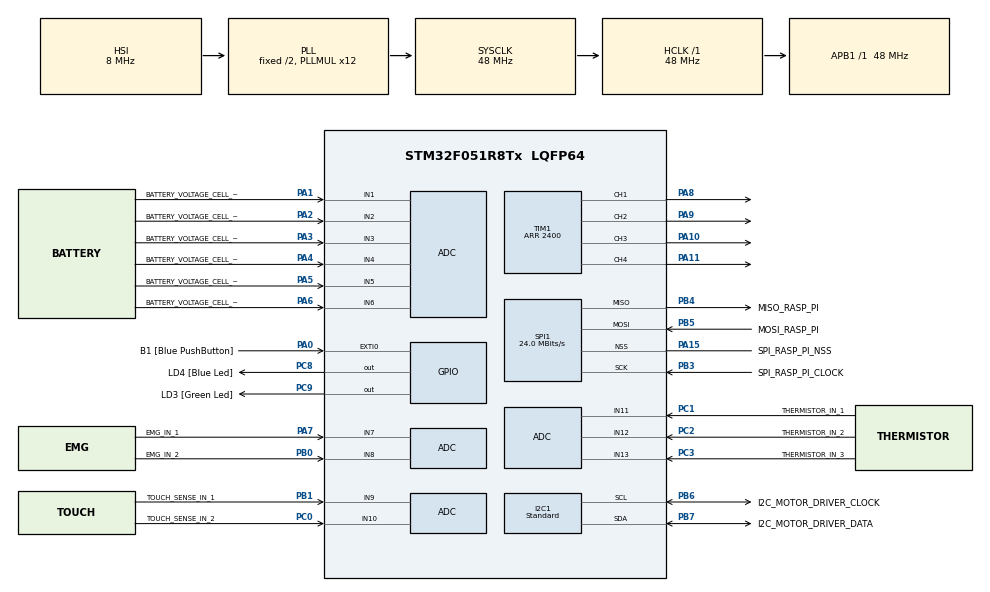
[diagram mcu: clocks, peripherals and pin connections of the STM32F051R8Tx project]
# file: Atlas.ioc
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ADC.ContinuousConvMode=ENABLE
ADC.DMAContinuousRequests=ENABLE
ADC.EOCSelection=EOC_SEQ_CONV
ADC.Overrun=OVR_DATA_OVERWRITTEN
ADC.SamplingTime=ADC_SAMPLETIME_55CYCLES_5
Dma.ADC.0.Direction=DMA_PERIPH_TO_MEMORY
Dma.ADC.0.Instance=DMA1_Channel1
Dma.ADC.0.MemDataAlignment=DMA_MDATAALIGN_HALFWORD
Dma.ADC.0.MemInc=DMA_MINC_ENABLE
Dma.ADC.0.Mode=DMA_CIRCULAR
Dma.ADC.0.PeriphDataAlignment=DMA_PDATAALIGN_HALFWORD
Dma.ADC.0.PeriphInc=DMA_PINC_DISABLE
Dma.ADC.0.Priority=DMA_PRIORITY_LOW
Dma.Request0=ADC
I2C1.I2C_Speed_Mode=I2C_Standard
I2C1.Speed=100
I2C1.Timing=0x2000090E
Mcu.Family=STM32F0
Mcu.Name=STM32F051R8Tx
Mcu.Package=LQFP64
NVIC.DMA1_Channel1_IRQn=true\:0\:0\:false
PA0.GPIO_Label=B1 [Blue PushButton]
PA0.GPIO_ModeDefaultEXTI=GPIO_MODE_EVT_RISING
PA0.GPIO_PuPd=GPIO_NOPULL
PA0.Signal=GPXTI0
PA1.GPIO_Label=BATTERY_VOLTAGE_CELL_IN_1
PA1.GPIO_Mode=GPIO_MODE_ANALOG
PA1.GPIO_PuPd=GPIO_NOPULL
PA1.Mode=IN1
PA1.Signal=ADC_IN1
PA10.Signal=S_TIM1_CH3
PA11.Signal=S_TIM1_CH4
PA13.GPIO_Label=SWDIO
PA13.Mode=Serial-WireDebug
PA13.Signal=SYS_SWDIO
PA14.GPIO_Label=SWCLK
PA14.Mode=Serial-WireDebug
PA14.Signal=SYS_SWCLK
PA15.GPIO_Label=SPI_RASP_PI_NSS
PA15.GPIO_Mode=GPIO_MODE_AF_PP
PA15.GPIO_PuPd=GPIO_NOPULL
PA15.GPIO_Speed=GPIO_SPEED_HIGH
PA15.Mode=NSS_Signal_Hard
PA15.Signal=SPI1_NSS
PA2.GPIO_Label=BATTERY_VOLTAGE_CELL_IN_2
PA2.GPIO_Mode=GPIO_MODE_ANALOG
PA2.GPIO_PuPd=GPIO_NOPULL
PA2.Mode=IN2
PA2.Signal=ADC_IN2
PA3.GPIO_Label=BATTERY_VOLTAGE_CELL_IN_3
PA3.GPIO_Mode=GPIO_MODE_ANALOG
PA3.GPIO_PuPd=GPIO_NOPULL
PA3.Mode=IN3
PA3.Signal=ADC_IN3
PA4.GPIO_Label=BATTERY_VOLTAGE_CELL_IN_4
PA4.GPIO_Mode=GPIO_MODE_ANALOG
PA4.GPIO_PuPd=GPIO_NOPULL
PA4.Mode=IN4
PA4.Signal=ADC_IN4
PA5.GPIO_Label=BATTERY_VOLTAGE_CELL_IN_5
PA5.GPIO_Mode=GPIO_MODE_ANALOG
PA5.GPIO_PuPd=GPIO_NOPULL
PA5.Mode=IN5
PA5.Signal=ADC_IN5
PA6.GPIO_Label=BATTERY_VOLTAGE_CELL_IN_6
PA6.GPIO_Mode=GPIO_MODE_ANALOG
PA6.GPIO_PuPd=GPIO_NOPULL
PA6.Mode=IN6
PA6.Signal=ADC_IN6
PA7.GPIO_Label=EMG_IN_1
PA7.GPIO_Mode=GPIO_MODE_ANALOG
PA7.GPIO_PuPd=GPIO_NOPULL
PA7.Mode=IN7
PA7.Signal=ADC_IN7
PA8.Signal=S_TIM1_CH1
PA9.Signal=S_TIM1_CH2
PB0.GPIO_Label=EMG_IN_2
PB0.GPIO_Mode=GPIO_MODE_ANALOG
PB0.GPIO_PuPd=GPIO_NOPULL
PB0.Mode=IN8
PB0.Signal=ADC_IN8
PB1.GPIO_Label=TOUCH_SENSE_IN_1
PB1.GPIO_Mode=GPIO_MODE_ANALOG
PB1.GPIO_PuPd=GPIO_NOPULL
PB1.Mode=IN9
PB1.Signal=ADC_IN9
PB3.GPIO_Label=SPI_RASP_PI_CLOCK
PB3.GPIO_Mode=GPIO_MODE_AF_PP
PB3.GPIO_PuPd=GPIO_NOPULL
PB3.GPIO_Speed=GPIO_SPEED_HIGH
PB3.Mode=Full_Duplex_Slave
PB3.Signal=SPI1_SCK
PB4.GPIO_Label=MISO_RASP_PI
PB4.GPIO_Mode=GPIO_MODE_AF_PP
PB4.GPIO_PuPd=GPIO_NOPULL
PB4.GPIO_Speed=GPIO_SPEED_HIGH
PB4.Mode=Full_Duplex_Slave
PB4.Signal=SPI1_MISO
PB5.GPIO_Label=MOSI_RASP_PI
PB5.GPIO_Mode=GPIO_MODE_AF_PP
PB5.GPIO_PuPd=GPIO_NOPULL
PB5.GPIO_Speed=GPIO_SPEED_HIGH
PB5.Mode=Full_Duplex_Slave
PB5.Signal=SPI1_MOSI
PB6.GPIO_FM6=__NULL
PB6.GPIO_Label=I2C_MOTOR_DRIVER_CLOCK
PB6.GPIO_Mode=GPIO_MODE_AF_OD
PB6.GPIO_PuPdOD=GPIO_PULLUP
PB6.GPIO_Speed=GPIO_SPEED_HIGH
PB6.Mode=I2C
PB6.Signal=I2C1_SCL
PB7.GPIO_FM7=__NULL
PB7.GPIO_Label=I2C_MOTOR_DRIVER_DATA
PB7.GPIO_Mode=GPIO_MODE_AF_OD
PB7.GPIO_PuPdOD=GPIO_PULLUP
PB7.GPIO_Speed=GPIO_SPEED_HIGH
PB7.Mode=I2C
PB7.Signal=I2C1_SDA
PC0.GPIO_Label=TOUCH_SENSE_IN_2
PC0.GPIO_Mode=GPIO_MODE_ANALOG
PC0.GPIO_PuPd=GPIO_NOPULL
PC0.Mode=IN10
PC0.Signal=ADC_IN10
PC1.GPIO_Label=THERMISTOR_IN_1
PC1.GPIO_Mode=GPIO_MODE_ANALOG
PC1.GPIO_PuPd=GPIO_NOPULL
PC1.Mode=IN11
PC1.Signal=ADC_IN11
PC2.GPIO_Label=THERMISTOR_IN_2
PC2.GPIO_Mode=GPIO_MODE_ANALOG
PC2.GPIO_PuPd=GPIO_NOPULL
PC2.Mode=IN12
PC2.Signal=ADC_IN12
PC3.GPIO_Label=THERMISTOR_IN_3
PC3.GPIO_Mode=GPIO_MODE_ANALOG
PC3.GPIO_PuPd=GPIO_NOPULL
PC3.Mode=IN13
PC3.Signal=ADC_IN13
PC8.GPIO_Label=LD4 [Blue Led]
PC8.GPIO_ModeDefaultOutputPP=GPIO_MODE_OUTPUT_PP
PC8.GPIO_PuPd=GPIO_NOPULL
PC8.GPIO_Speed=GPIO_SPEED_LOW
PC8.Signal=GPIO_Output
PC9.GPIO_Label=LD3 [Green Led]
PC9.GPIO_ModeDefaultOutputPP=GPIO_MODE_OUTPUT_PP
PC9.GPIO_PuPd=GPIO_NOPULL
PC9.GPIO_Speed=GPIO_SPEED_LOW
PC9.Signal=GPIO_Output
ProjectManager.TargetToolchain=MDK-ARM V5
RCC.AHBFreq_Value=48000000
RCC.APB1Freq_Value=48000000
RCC.APB1TimFreq_Value=48000000
RCC.HCLKFreq_Value=48000000
RCC.PLLMUL=RCC_PLL_MUL12
RCC.SYSCLKFreq_VALUE=48000000
RCC.SYSCLKSource=RCC_SYSCLKSOURCE_PLLCLK
SH.S_TIM1_CH1.0=TIM1_CH1,Output Compare1 CH1
SH.S_TIM1_CH2.0=TIM1_CH2,Output Compare2 CH2
SH.S_TIM1_CH3.0=TIM1_CH3,Output Compare3 CH3
SH.S_TIM1_CH4.0=TIM1_CH4,Output Compare4 CH4
SPI1.CalculateBaudRate=24.0 MBits/s
SPI1.DataSize=SPI_DATASIZE_8BIT
SPI1.VirtualNSS=VM_NSSHARD
SPI1.VirtualType=VM_SLAVE
TIM1.Channel-Output\ Compare2\ CH2=TIM_CHANNEL_2
TIM1.Channel-Output\ Compare3\ CH3=TIM_CHANNEL_3
TIM1.Channel-Output\ Compare4\ CH4=TIM_CHANNEL_4
TIM1.OCMode_1=TIM_OCMODE_INACTIVE
TIM1.OCMode_2=TIM_OCMODE_INACTIVE
TIM1.Period=2400
VP_ADC_TempSens_Input.Mode=IN-TempSens
VP_TIM1_VS_ClockSourceINT.Mode=Internal
board=STM32F0DISCOVERY

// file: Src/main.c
/**
  ******************************************************************************
  * File Name          : main.c
  * Description        : Main program body
  ******************************************************************************
  *
  * COPYRIGHT(c) 2016 STMicroelectronics
  *
  * Redistribution and use in source and binary forms, with or without modification,
  * are permitted provided that the following conditions are met:
  *   1. Redistributions of source code must retain the above copyright notice,
  *      this list of conditions and the following disclaimer.
  *   2. Redistributions in binary form must reproduce the above copyright notice,
  *      this list of conditions and the following disclaimer in the documentation
  *      and/or other materials provided with the distribution.
  *   3. Neither the name of STMicroelectronics nor the names of its contributors
  *      may be used to endorse or promote products derived from this software
  *      without specific prior written permission.
  *
  * THIS SOFTWARE IS PROVIDED BY THE COPYRIGHT HOLDERS AND CONTRIBUTORS "AS IS"
  * AND ANY EXPRESS OR IMPLIED WARRANTIES, INCLUDING, BUT NOT LIMITED TO, THE
  * IMPLIED WARRANTIES OF MERCHANTABILITY AND FITNESS FOR A PARTICULAR PURPOSE ARE
  * DISCLAIMED. IN NO EVENT SHALL THE COPYRIGHT HOLDER OR CONTRIBUTORS BE LIABLE
  * FOR ANY DIRECT, INDIRECT, INCIDENTAL, SPECIAL, EXEMPLARY, OR CONSEQUENTIAL
  * DAMAGES (INCLUDING, BUT NOT LIMITED TO, PROCUREMENT OF SUBSTITUTE GOODS OR
  * SERVICES; LOSS OF USE, DATA, OR PROFITS; OR BUSINESS INTERRUPTION) HOWEVER
  * CAUSED AND ON ANY THEORY OF LIABILITY, WHETHER IN CONTRACT, STRICT LIABILITY,
  * OR TORT (INCLUDING NEGLIGENCE OR OTHERWISE) ARISING IN ANY WAY OUT OF THE USE
  * OF THIS SOFTWARE, EVEN IF ADVISED OF THE POSSIBILITY OF SUCH DAMAGE.
  *
  ******************************************************************************
  */
#include "stm32f0xx_hal.h"
#include "adc.h"
#include "dma.h"
#include "i2c.h"
#include "spi.h"
#include "tim.h"
#include "gpio.h"

/* USER CODE BEGIN Includes */
#define SYSTEM_TICK   100 // in milliseconds

/* USER CODE END Includes */

/* USER CODE BEGIN PV */
/* Private variables ---------------------------------------------------------*/
uint32_t	current_time, last_time;
uint16_t	count = 100, updown = 1;
uint16_t  a, b;

/* USER CODE END PV */

void SystemClock_Config(void);

/* USER CODE BEGIN PFP */
/* Private function prototypes -----------------------------------------------*/

/* USER CODE END PFP */

int main(void)
{

  /* MCU Configuration----------------------------------------------------------*/

  /* Reset of all peripherals, Initializes the Flash interface and the Systick. */
  HAL_Init();

  /* Configure the system clock */
  SystemClock_Config();

  /* Initialize all configured peripherals */
  MX_GPIO_Init();
  MX_DMA_Init();
  MX_ADC_Init();
  MX_I2C1_Init();
  MX_SPI1_Init();
  MX_TIM1_Init();

  /* USER CODE BEGIN 2 */

	ADC_configDMA();
 	TIM_initTimers();
	last_time = HAL_GetTick();

  /* USER CODE END 2 */

  /* Infinite loop */
  /* USER CODE BEGIN WHILE */
  while (1)
  {

		current_time = HAL_GetTick();
		if ((current_time - last_time) >= SYSTEM_TICK )
		{
			last_time = current_time;

		}
  /* USER CODE END WHILE */

  }

}

/** System Clock Configuration
*/
void SystemClock_Config(void)
{

  RCC_OscInitTypeDef RCC_OscInitStruct;
  RCC_ClkInitTypeDef RCC_ClkInitStruct;
  RCC_PeriphCLKInitTypeDef PeriphClkInit;

  RCC_OscInitStruct.OscillatorType = RCC_OSCILLATORTYPE_HSI|RCC_OSCILLATORTYPE_HSI14;
  RCC_OscInitStruct.HSIState = RCC_HSI_ON;
  RCC_OscInitStruct.HSI14State = RCC_HSI14_ON;
  RCC_OscInitStruct.HSICalibrationValue = 16;
  RCC_OscInitStruct.HSI14CalibrationValue = 16;
  RCC_OscInitStruct.PLL.PLLState = RCC_PLL_ON;
  RCC_OscInitStruct.PLL.PLLSource = RCC_PLLSOURCE_HSI;
  RCC_OscInitStruct.PLL.PLLMUL = RCC_PLL_MUL12;
  RCC_OscInitStruct.PLL.PREDIV = RCC_PREDIV_DIV1;
  HAL_RCC_OscConfig(&RCC_OscInitStruct);

  RCC_ClkInitStruct.ClockType = RCC_CLOCKTYPE_SYSCLK;
  RCC_ClkInitStruct.SYSCLKSource = RCC_SYSCLKSOURCE_PLLCLK;
  RCC_ClkInitStruct.AHBCLKDivider = RCC_SYSCLK_DIV1;
  RCC_ClkInitStruct.APB1CLKDivider = RCC_HCLK_DIV1;
  HAL_RCC_ClockConfig(&RCC_ClkInitStruct, FLASH_LATENCY_1);

  PeriphClkInit.PeriphClockSelection = RCC_PERIPHCLK_I2C1;
  PeriphClkInit.I2c1ClockSelection = RCC_I2C1CLKSOURCE_HSI;
  HAL_RCCEx_PeriphCLKConfig(&PeriphClkInit);

  HAL_SYSTICK_Config(HAL_RCC_GetHCLKFreq()/1000);

  HAL_SYSTICK_CLKSourceConfig(SYSTICK_CLKSOURCE_HCLK);

}

/************************ (C) COPYRIGHT STMicroelectronics *****END OF FILE****/
